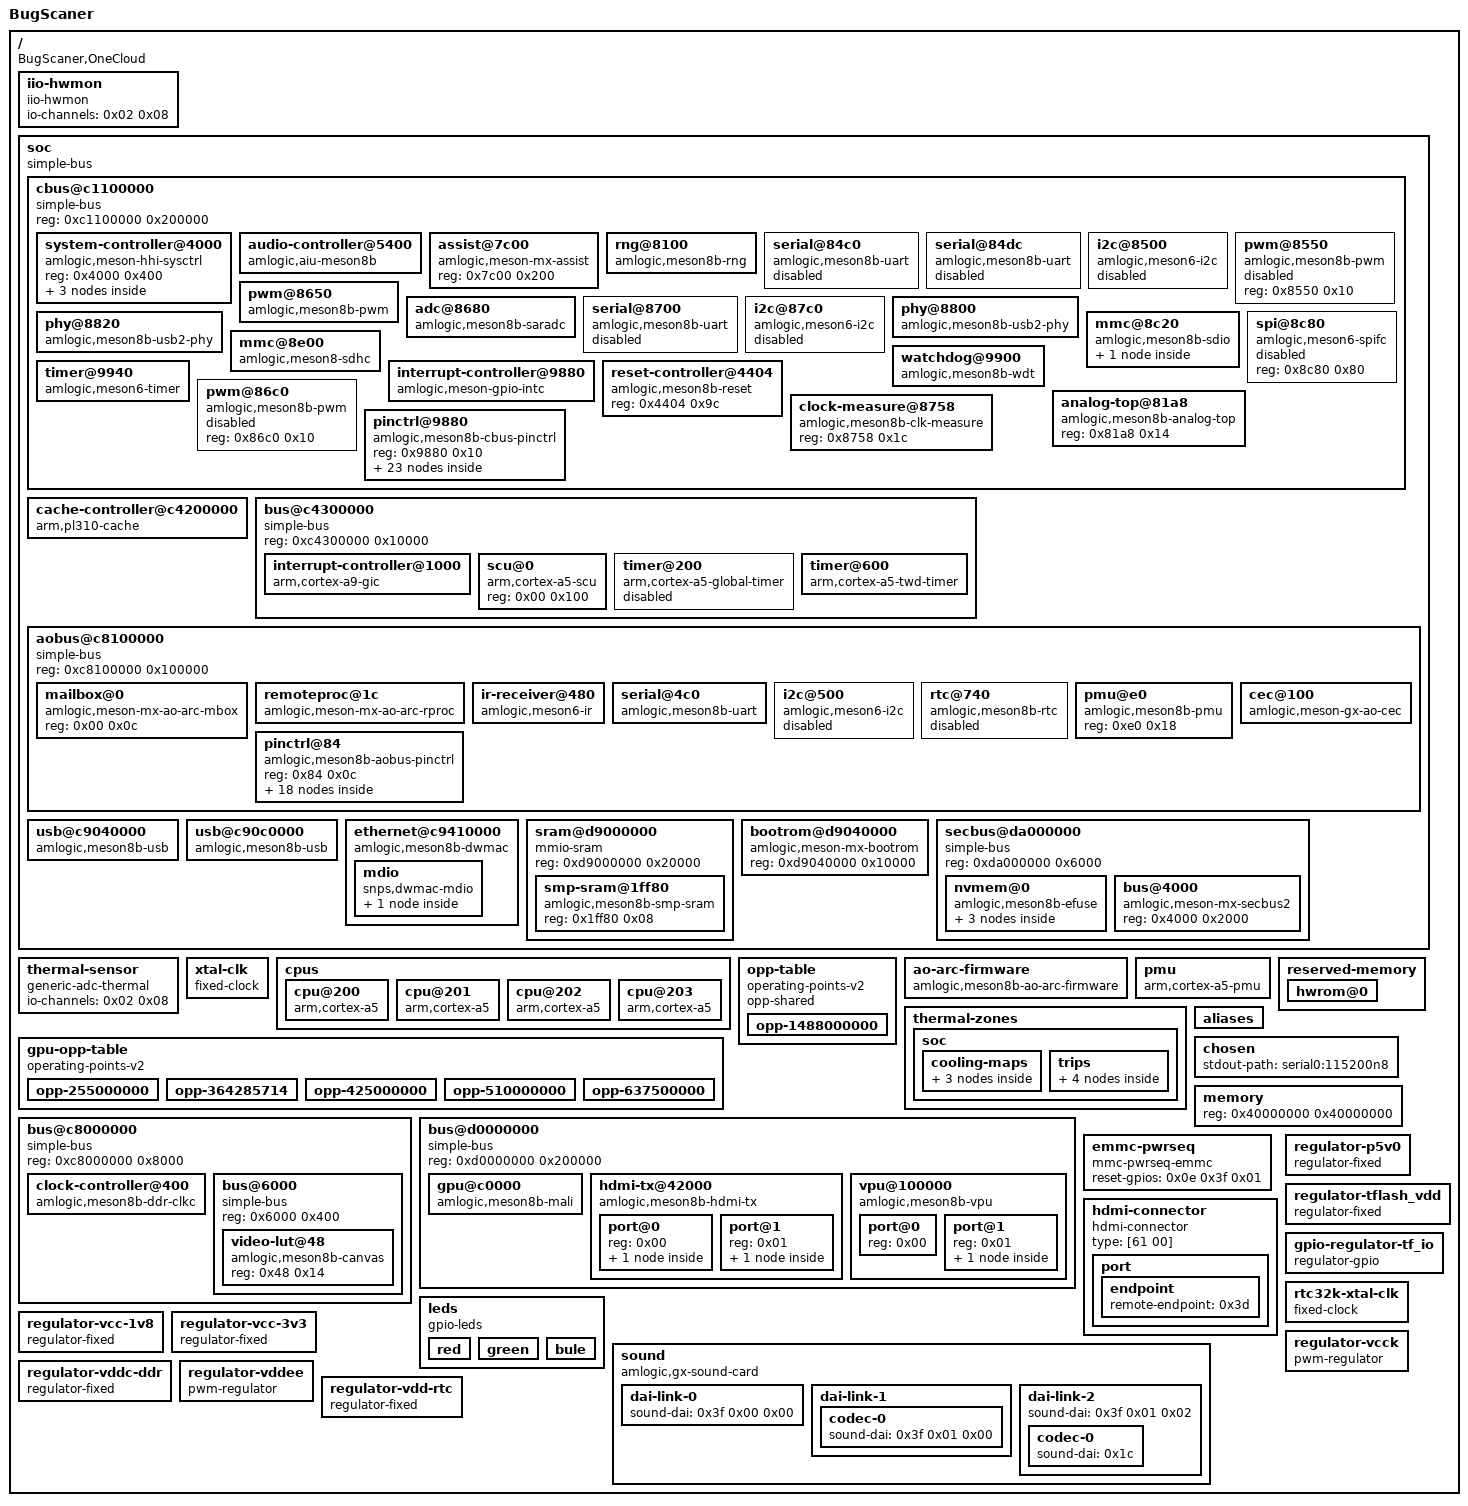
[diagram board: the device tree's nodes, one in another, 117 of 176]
/dts-v1/;

/ {
	#address-cells = <0x01>;
	#size-cells = <0x01>;
	interrupt-parent = <0x01>;
	model = "BugScaner";
	compatible = "BugScaner,OneCloud\0amlogic,meson8b";

	iio-hwmon {
		compatible = "iio-hwmon";
		io-channels = <0x02 0x08>;
	};

	soc {
		compatible = "simple-bus";
		#address-cells = <0x01>;
		#size-cells = <0x01>;
		ranges;

		cbus@c1100000 {
			compatible = "simple-bus";
			reg = <0xc1100000 0x200000>;
			#address-cells = <0x01>;
			#size-cells = <0x01>;
			ranges = <0x00 0xc1100000 0x200000>;

			system-controller@4000 {
				compatible = "amlogic,meson-hhi-sysctrl\0simple-mfd\0syscon";
				reg = <0x4000 0x400>;
				phandle = <0x0a>;

				clock-controller {
					compatible = "amlogic,meson8b-clkc";
					clocks = <0x03 0x04 0x01>;
					clock-names = "xtal\0ddr_pll";
					#clock-cells = <0x01>;
					#reset-cells = <0x01>;
					phandle = <0x05>;
				};

				phy {
					compatible = "amlogic,meson8b-hdmi-tx-phy";
					clocks = <0x05 0x84>;
					#phy-cells = <0x00>;
					phandle = <0x35>;
				};

				power-controller {
					compatible = "amlogic,meson8b-pwrc";
					#power-domain-cells = <0x01>;
					amlogic,ao-sysctrl = <0x06>;
					resets = <0x07 0x42 0x07 0x43 0x07 0x4b 0x07 0x4f 0x07 0x86 0x07 0x87 0x07 0x89 0x07 0x8d 0x07 0x05 0x07 0x0a 0x07 0x85>;
					reset-names = "dblk\0pic_dc\0hdmi_apb\0hdmi_system\0venci\0vencp\0vdac\0vencl\0viu\0venc\0rdma";
					clocks = <0x05 0xbe>;
					clock-names = "vpu";
					assigned-clocks = <0x05 0xbe>;
					assigned-clock-rates = <0xadb4789>;
					phandle = <0x20>;
				};
			};

			audio-controller@5400 {
				compatible = "amlogic,aiu-meson8b\0amlogic,aiu";
				#sound-dai-cells = <0x02>;
				reg = <0x5400 0x2ac>;
				interrupts = <0x00 0x30 0x01 0x00 0x32 0x01>;
				interrupt-names = "i2s\0spdif";
				status = "okay";
				clocks = <0x05 0x26 0x05 0x28 0x05 0x50 0x05 0xd1 0x05 0x2c 0x05 0x27 0x05 0x51 0x05 0xd4 0x05 0xd5>;
				clock-names = "pclk\0i2s_pclk\0i2s_aoclk\0i2s_mclk\0i2s_mixer\0spdif_pclk\0spdif_aoclk\0spdif_mclk\0spdif_mclk_sel";
				resets = <0x07 0x06>;
				phandle = <0x3f>;
			};

			assist@7c00 {
				compatible = "amlogic,meson-mx-assist\0syscon";
				reg = <0x7c00 0x200>;
			};

			rng@8100 {
				compatible = "amlogic,meson8b-rng\0amlogic,meson-rng";
				reg = <0x8100 0x08>;
				clocks = <0x05 0x19>;
				clock-names = "core";
			};

			serial@84c0 {
				compatible = "amlogic,meson8b-uart\0amlogic,meson-uart";
				reg = <0x84c0 0x18>;
				interrupts = <0x00 0x1a 0x01>;
				status = "disabled";
				clocks = <0x05 0x0a 0x03 0x05 0x1a>;
				clock-names = "baud\0xtal\0pclk";
			};

			serial@84dc {
				compatible = "amlogic,meson8b-uart\0amlogic,meson-uart";
				reg = <0x84dc 0x18>;
				interrupts = <0x00 0x4b 0x01>;
				status = "disabled";
				clocks = <0x05 0x0a 0x03 0x05 0x30>;
				clock-names = "baud\0xtal\0pclk";
			};

			i2c@8500 {
				compatible = "amlogic,meson6-i2c";
				reg = <0x8500 0x20>;
				interrupts = <0x00 0x15 0x01>;
				#address-cells = <0x01>;
				#size-cells = <0x00>;
				status = "disabled";
				clocks = <0x05 0x16>;
			};

			pwm@8550 {
				compatible = "amlogic,meson8b-pwm";
				reg = <0x8550 0x10>;
				#pwm-cells = <0x03>;
				status = "disabled";
			};

			pwm@8650 {
				compatible = "amlogic,meson8b-pwm";
				reg = <0x8650 0x10>;
				#pwm-cells = <0x03>;
				status = "okay";
				pinctrl-0 = <0x08 0x09>;
				pinctrl-names = "default";
				clocks = <0x03 0x03>;
				clock-names = "clkin0\0clkin1";
				phandle = <0x41>;
			};

			adc@8680 {
				compatible = "amlogic,meson8b-saradc\0amlogic,meson-saradc";
				reg = <0x8680 0x34>;
				#io-channel-cells = <0x01>;
				interrupts = <0x00 0x49 0x01>;
				status = "okay";
				clocks = <0x03 0x05 0x17>;
				clock-names = "clkin\0core";
				amlogic,hhi-sysctrl = <0x0a>;
				nvmem-cells = <0x0b>;
				nvmem-cell-names = "temperature_calib";
				vref-supply = <0x0c>;
				phandle = <0x02>;
			};

			serial@8700 {
				compatible = "amlogic,meson8b-uart\0amlogic,meson-uart";
				reg = <0x8700 0x18>;
				interrupts = <0x00 0x5d 0x01>;
				status = "disabled";
				clocks = <0x05 0x0a 0x03 0x05 0x44>;
				clock-names = "baud\0xtal\0pclk";
			};

			i2c@87c0 {
				compatible = "amlogic,meson6-i2c";
				reg = <0x87c0 0x20>;
				interrupts = <0x00 0x80 0x01>;
				#address-cells = <0x01>;
				#size-cells = <0x00>;
				status = "disabled";
				clocks = <0x05 0x16>;
			};

			phy@8800 {
				compatible = "amlogic,meson8b-usb2-phy\0amlogic,meson-mx-usb2-phy";
				#phy-cells = <0x00>;
				reg = <0x8800 0x20>;
				status = "okay";
				clocks = <0x05 0x37 0x05 0x32>;
				clock-names = "usb_general\0usb";
				resets = <0x07 0x22>;
				phandle = <0x1d>;
			};

			phy@8820 {
				compatible = "amlogic,meson8b-usb2-phy\0amlogic,meson-mx-usb2-phy";
				#phy-cells = <0x00>;
				reg = <0x8820 0x20>;
				status = "okay";
				clocks = <0x05 0x37 0x05 0x33>;
				clock-names = "usb_general\0usb";
				resets = <0x07 0x22>;
				phandle = <0x1f>;
			};

			mmc@8c20 {
				compatible = "amlogic,meson8b-sdio\0amlogic,meson-mx-sdio";
				reg = <0x8c20 0x20>;
				interrupts = <0x00 0x1c 0x01>;
				#address-cells = <0x01>;
				#size-cells = <0x00>;
				status = "okay";
				clocks = <0x05 0x1e 0x05 0x0a>;
				clock-names = "core\0clkin";
				pinctrl-0 = <0x0d>;
				pinctrl-names = "default";

				slot@1 {
					compatible = "mmc-slot";
					reg = <0x01>;
					status = "okay";
					bus-width = <0x04>;
					no-sdio;
					cap-mmc-highspeed;
					cap-sd-highspeed;
					disable-wp;
					cd-gpios = <0x0e 0x35 0x01>;
					vmmc-supply = <0x0f>;
					vqmmc-supply = <0x10>;
				};
			};

			spi@8c80 {
				compatible = "amlogic,meson6-spifc";
				reg = <0x8c80 0x80>;
				#address-cells = <0x01>;
				#size-cells = <0x00>;
				status = "disabled";
			};

			mmc@8e00 {
				compatible = "amlogic,meson8-sdhc\0amlogic,meson-mx-sdhc";
				reg = <0x8e00 0x42>;
				interrupts = <0x00 0x4e 0x01>;
				status = "okay";
				clocks = <0x03 0x05 0x07 0x05 0x06 0x05 0x08 0x05 0x1b>;
				clock-names = "clkin0\0clkin1\0clkin2\0clkin3\0pclk";
				pinctrl-0 = <0x11>;
				pinctrl-names = "default";
				bus-width = <0x08>;
				max-frequency = <0x5f5e100>;
				disable-wp;
				cap-mmc-highspeed;
				mmc-hs200-1_8v;
				no-sdio;
				mmc-pwrseq = <0x12>;
				vmmc-supply = <0x13>;
				vqmmc-supply = <0x0c>;
			};

			interrupt-controller@9880 {
				compatible = "amlogic,meson-gpio-intc\0amlogic,meson8b-gpio-intc";
				reg = <0x9880 0x10>;
				interrupt-controller;
				#interrupt-cells = <0x02>;
				amlogic,channel-interrupts = <0x40 0x41 0x42 0x43 0x44 0x45 0x46 0x47>;
				status = "okay";
				phandle = <0x24>;
			};

			watchdog@9900 {
				compatible = "amlogic,meson8b-wdt";
				reg = <0x9900 0x08>;
				interrupts = <0x00 0x00 0x01>;
			};

			timer@9940 {
				compatible = "amlogic,meson6-timer";
				reg = <0x9940 0x18>;
				interrupts = <0x00 0x0a 0x01 0x00 0x0b 0x01 0x00 0x06 0x01 0x00 0x1d 0x01>;
				clocks = <0x03 0x05 0x0a>;
				clock-names = "xtal\0pclk";
			};

			reset-controller@4404 {
				compatible = "amlogic,meson8b-reset";
				reg = <0x4404 0x9c>;
				#reset-cells = <0x01>;
				phandle = <0x07>;
			};

			analog-top@81a8 {
				compatible = "amlogic,meson8b-analog-top\0syscon";
				reg = <0x81a8 0x14>;
			};

			pwm@86c0 {
				compatible = "amlogic,meson8b-pwm";
				reg = <0x86c0 0x10>;
				#pwm-cells = <0x03>;
				status = "disabled";
			};

			clock-measure@8758 {
				compatible = "amlogic,meson8b-clk-measure";
				reg = <0x8758 0x1c>;
			};

			pinctrl@9880 {
				compatible = "amlogic,meson8b-cbus-pinctrl";
				reg = <0x9880 0x10>;
				#address-cells = <0x01>;
				#size-cells = <0x01>;
				ranges;
				phandle = <0x14>;

				banks@80b0 {
					reg = <0x80b0 0x28 0x80e8 0x18 0x8120 0x18 0x8030 0x38>;
					reg-names = "mux\0pull\0pull-enable\0gpio";
					gpio-controller;
					#gpio-cells = <0x02>;
					gpio-ranges = <0x14 0x00 0x00 0x53>;
					gpio-line-names = "J2 Header Pin 35\0J2 Header Pin 36\0J2 Header Pin 32\0J2 Header Pin 31\0J2 Header Pin 29\0J2 Header Pin 18\0J2 Header Pin 22\0J2 Header Pin 16\0J2 Header Pin 23\0J2 Header Pin 21\0J2 Header Pin 19\0J2 Header Pin 33\0J2 Header Pin 8\0J2 Header Pin 10\0J2 Header Pin 15\0J2 Header Pin 13\0J2 Header Pin 24\0J2 Header Pin 26\0Revision (upper)\0Revision (lower)\0J2 Header Pin 7\0\0J2 Header Pin 12\0J2 Header Pin 11\0\0\0\0TFLASH_VDD_EN\0\0\0VCCK_PWM (PWM_C)\0I2CA_SDA\0I2CA_SCL\0I2CB_SDA\0I2CB_SCL\0VDDEE_PWM (PWM_D)\0\0HDMI_HPD\0HDMI_I2C_SDA\0HDMI_I2C_SCL\0ETH_PHY_INTR\0ETH_PHY_NRST\0ETH_TXD1\0ETH_TXD0\0ETH_TXD3\0ETH_TXD2\0ETH_RGMII_TX_CLK\0SD_DATA1 (SDB_D1)\0SD_DATA0 (SDB_D0)\0SD_CLK\0SD_CMD\0SD_DATA3 (SDB_D3)\0SD_DATA2 (SDB_D2)\0SD_CDN (SD_DET_N)\0SDC_D0 (EMMC)\0SDC_D1 (EMMC)\0SDC_D2 (EMMC)\0SDC_D3 (EMMC)\0SDC_D4 (EMMC)\0SDC_D5 (EMMC)\0SDC_D6 (EMMC)\0SDC_D7 (EMMC)\0SDC_CLK (EMMC)\0SDC_RSTn (EMMC)\0SDC_CMD (EMMC)\0BOOT_SEL\0\0\0\0\0\0\0\0ETH_RXD1\0ETH_RXD0\0ETH_RX_DV\0RGMII_RX_CLK\0ETH_RXD3\0ETH_RXD2\0ETH_TXEN\0ETH_PHY_REF_CLK_25MOUT\0ETH_MDC\0ETH_MDIO";
					phandle = <0x0e>;
				};

				eth-rgmii {
					phandle = <0x21>;

					mux {
						groups = "eth_tx_clk\0eth_tx_en\0eth_txd1_0\0eth_txd0_0\0eth_rx_clk\0eth_rx_dv\0eth_rxd1\0eth_rxd0\0eth_mdio_en\0eth_mdc\0eth_ref_clk\0eth_txd2\0eth_txd3\0eth_rxd3\0eth_rxd2";
						function = "ethernet";
						bias-disable;
					};
				};

				eth-rmii {

					mux {
						groups = "eth_tx_en\0eth_txd1_0\0eth_txd0_0\0eth_rx_clk\0eth_rx_dv\0eth_rxd1\0eth_rxd0\0eth_mdio_en\0eth_mdc";
						function = "ethernet";
						bias-disable;
					};
				};

				hdmi-hpd {
					phandle = <0x36>;

					mux {
						groups = "hdmi_hpd";
						function = "hdmi";
						bias-disable;
					};
				};

				hdmi-i2c {
					phandle = <0x37>;

					mux {
						groups = "hdmi_sda\0hdmi_scl";
						function = "hdmi";
						bias-disable;
					};
				};

				i2c-a {

					mux {
						groups = "i2c_sda_a\0i2c_sck_a";
						function = "i2c_a";
						bias-disable;
					};
				};

				sd-b {
					phandle = <0x0d>;

					mux {
						groups = "sd_d0_b\0sd_d1_b\0sd_d2_b\0sd_d3_b\0sd_clk_b\0sd_cmd_b";
						function = "sd_b";
						bias-disable;
					};
				};

				sdxc-c {
					phandle = <0x11>;

					mux {
						groups = "sdxc_d0_c\0sdxc_d13_c\0sdxc_d47_c\0sdxc_clk_c\0sdxc_cmd_c";
						function = "sdxc_c";
						bias-pull-up;
					};
				};

				pwm-c1 {
					phandle = <0x08>;

					mux {
						groups = "pwm_c1";
						function = "pwm_c";
						bias-disable;
					};
				};

				pwm-d {
					phandle = <0x09>;

					mux {
						groups = "pwm_d";
						function = "pwm_d";
						bias-disable;
					};
				};

				uart-b0 {

					mux {
						groups = "uart_tx_b0\0uart_rx_b0";
						function = "uart_b";
						bias-disable;
					};
				};

				uart-b0-cts-rts {

					mux {
						groups = "uart_cts_b0\0uart_rts_b0";
						function = "uart_b";
						bias-disable;
					};
				};
			};
		};

		cache-controller@c4200000 {
			compatible = "arm,pl310-cache";
			reg = <0xc4200000 0x1000>;
			cache-unified;
			cache-level = <0x02>;
			arm,data-latency = <0x03 0x03 0x03>;
			arm,tag-latency = <0x02 0x02 0x02>;
			arm,filter-ranges = <0x100000 0xc0000000>;
			prefetch-data = <0x01>;
			prefetch-instr = <0x01>;
			arm,shared-override;
			phandle = <0x25>;
		};

		bus@c4300000 {
			compatible = "simple-bus";
			reg = <0xc4300000 0x10000>;
			#address-cells = <0x01>;
			#size-cells = <0x01>;
			ranges = <0x00 0xc4300000 0x10000>;

			interrupt-controller@1000 {
				compatible = "arm,cortex-a9-gic";
				reg = <0x1000 0x1000 0x100 0x100>;
				interrupt-controller;
				#interrupt-cells = <0x03>;
				phandle = <0x01>;
			};

			scu@0 {
				compatible = "arm,cortex-a5-scu";
				reg = <0x00 0x100>;
			};

			timer@200 {
				compatible = "arm,cortex-a5-global-timer";
				reg = <0x200 0x20>;
				interrupts = <0x01 0x0b 0xf01>;
				clocks = <0x05 0x7e>;
				status = "disabled";
			};

			timer@600 {
				compatible = "arm,cortex-a5-twd-timer";
				reg = <0x600 0x20>;
				interrupts = <0x01 0x0d 0xf01>;
				clocks = <0x05 0x7e>;
			};
		};

		aobus@c8100000 {
			compatible = "simple-bus";
			reg = <0xc8100000 0x100000>;
			#address-cells = <0x01>;
			#size-cells = <0x01>;
			ranges = <0x00 0xc8100000 0x100000>;

			mailbox@0 {
				compatible = "amlogic,meson-mx-ao-arc-mbox";
				reg = <0x00 0x0c>;
				#mbox-cells = <0x01>;
				phandle = <0x29>;
			};

			remoteproc@1c {
				compatible = "amlogic,meson-mx-ao-arc-rproc";
				reg = <0x1c 0x08 0x38 0x08>;
				reg-names = "remap\0cpu";
				amlogic,sram = <0x15>;
				amlogic,secbus2 = <0x16>;
				resets = <0x07 0x4d>;
				reset-names = "arc625";
				phandle = <0x28>;
			};

			ir-receiver@480 {
				compatible = "amlogic,meson6-ir";
				reg = <0x480 0x20>;
				interrupts = <0x00 0x0f 0x01>;
				status = "okay";
				pinctrl-0 = <0x17>;
				pinctrl-names = "default";
			};

			serial@4c0 {
				compatible = "amlogic,meson8b-uart\0amlogic,meson-uart";
				reg = <0x4c0 0x18>;
				interrupts = <0x00 0x5a 0x01>;
				status = "okay";
				clocks = <0x05 0x0a 0x03 0x05 0x0a>;
				clock-names = "baud\0xtal\0pclk";
				pinctrl-0 = <0x18>;
				pinctrl-names = "default";
			};

			i2c@500 {
				compatible = "amlogic,meson6-i2c";
				reg = <0x500 0x20>;
				interrupts = <0x00 0x5c 0x01>;
				#address-cells = <0x01>;
				#size-cells = <0x00>;
				status = "disabled";
				clocks = <0x05 0x0a>;
			};

			rtc@740 {
				compatible = "amlogic,meson8b-rtc";
				reg = <0x740 0x14>;
				interrupts = <0x00 0x48 0x01>;
				#address-cells = <0x01>;
				#size-cells = <0x01>;
				status = "disabled";
				resets = <0x07 0x8a>;
				clocks = <0x19>;
				vdd-supply = <0x1a>;
			};

			pmu@e0 {
				compatible = "amlogic,meson8b-pmu\0syscon";
				reg = <0xe0 0x18>;
				phandle = <0x06>;
			};

			pinctrl@84 {
				compatible = "amlogic,meson8b-aobus-pinctrl";
				reg = <0x84 0x0c>;
				#address-cells = <0x01>;
				#size-cells = <0x01>;
				ranges;
				phandle = <0x1b>;

				ao-bank@14 {
					reg = <0x14 0x04 0x2c 0x04 0x24 0x08>;
					reg-names = "mux\0pull\0gpio";
					gpio-controller;
					#gpio-cells = <0x02>;
					gpio-ranges = <0x1b 0x00 0x00 0x10>;
					gpio-line-names = "UART TX\0UART RX\0\0TF_3V3N_1V8_EN\0USB_HUB_RST_N\0USB_OTG_PWREN\0J7 Header Pin 2\0IR_IN\0J7 Header Pin 4\0J7 Header Pin 6\0J7 Header Pin 5\0J7 Header Pin 7\0HDMI_CEC\0SYS_LED\0\0";
					phandle = <0x3e>;

					usb-hub {
						gpio-hog;
						gpios = <0x04 0x00>;
						output-high;
						line-name = "usb-hub-reset";
					};
				};

				hdmi-cec-ao {

					mux {
						groups = "hdmi_cec_1";
						function = "hdmi_cec";
						bias-pull-up;
					};
				};

				i2s-am-clk-out {

					mux {
						groups = "i2s_am_clk_out";
						function = "i2s";
						bias-disable;
					};
				};

				i2s-ao-clk-out {

					mux {
						groups = "i2s_ao_clk_out";
						function = "i2s";
						bias-disable;
					};
				};

				i2s-lr-clk-out {

					mux {
						groups = "i2s_lr_clk_out";
						function = "i2s";
						bias-disable;
					};
				};

				i2s-out-ch01 {

					mux {
						groups = "i2s_out_01";
						function = "i2s";
						bias-disable;
					};
				};

				spdif-out-1 {

					mux {
						groups = "spdif_out_1";
						function = "spdif_1";
						bias-disable;
					};
				};

				uart_ao_a {
					phandle = <0x18>;

					mux {
						groups = "uart_tx_ao_a\0uart_rx_ao_a";
						function = "uart_ao";
						bias-disable;
					};
				};

				remote {
					phandle = <0x17>;

					mux {
						groups = "remote_input";
						function = "remote";
						bias-disable;
					};
				};
			};

			cec@100 {
				compatible = "amlogic,meson-gx-ao-cec";
				reg = <0x100 0x14>;
				interrupts = <0x00 0x97 0x01>;
				hdmi-phandle = <0x1c>;
			};
		};

		usb@c9040000 {
			compatible = "amlogic,meson8b-usb\0snps,dwc2";
			#address-cells = <0x01>;
			#size-cells = <0x00>;
			reg = <0xc9040000 0x40000>;
			interrupts = <0x00 0x1e 0x04>;
			phys = <0x1d>;
			phy-names = "usb2-phy";
			g-rx-fifo-size = <0x200>;
			g-np-tx-fifo-size = <0x1f4>;
			g-tx-fifo-size = <0x100 0xc0 0x80 0x80 0x80>;
			dr_mode = "peripheral";
			status = "okay";
			clocks = <0x05 0x41>;
			clock-names = "otg";
		};

		usb@c90c0000 {
			compatible = "amlogic,meson8b-usb\0snps,dwc2";
			#address-cells = <0x01>;
			#size-cells = <0x00>;
			reg = <0xc90c0000 0x40000>;
			interrupts = <0x00 0x1f 0x04>;
			phys = <0x1f>;
			phy-names = "usb2-phy";
			dr_mode = "host";
			status = "okay";
			clocks = <0x05 0x40>;
			clock-names = "otg";
		};

		ethernet@c9410000 {
			compatible = "amlogic,meson8b-dwmac\0snps,dwmac-3.70a\0snps,dwmac";
			reg = <0xc9410000 0x10000 0xc1108140 0x04>;
			interrupts = <0x00 0x08 0x04>;
			interrupt-names = "macirq";
			status = "okay";
			clocks = <0x05 0x24 0x05 0x5f 0x05 0x5f 0x05 0x05>;
			clock-names = "stmmaceth\0clkin0\0clkin1\0timing-adjustment";
			rx-fifo-depth = <0x1000>;
			tx-fifo-depth = <0x800>;
			resets = <0x07 0x2b>;
			reset-names = "stmmaceth";
			power-domains = <0x20 0x01>;
			pinctrl-0 = <0x21>;
			pinctrl-names = "default";
			phy-handle = <0x22>;
			phy-mode = "rgmii-rxid";
			nvmem-cells = <0x23>;
			nvmem-cell-names = "mac-address";

			mdio {
				compatible = "snps,dwmac-mdio";
				#address-cells = <0x01>;
				#size-cells = <0x00>;

				ethernet-phy@0 {
					reg = <0x00>;
					reset-assert-us = <0x2710>;
					reset-deassert-us = <0x7530>;
					reset-gpios = <0x0e 0x29 0x01>;
					interrupt-parent = <0x24>;
					interrupts = <0x11 0x08>;
					realtek,led-0-mode = <0x00>;
					realtek,led-1-mode = <0x1a>;
					realtek,led-2-mode = <0x1c>;
					phandle = <0x22>;
				};
			};
		};

		sram@d9000000 {
			compatible = "mmio-sram";
			reg = <0xd9000000 0x20000>;
			#address-cells = <0x01>;
			#size-cells = <0x01>;
			ranges = <0x00 0xd9000000 0x20000>;
			phandle = <0x15>;

			smp-sram@1ff80 {
				compatible = "amlogic,meson8b-smp-sram";
				reg = <0x1ff80 0x08>;
			};
		};

		bootrom@d9040000 {
			compatible = "amlogic,meson-mx-bootrom\0syscon";
			reg = <0xd9040000 0x10000>;
		};

		secbus@da000000 {
			compatible = "simple-bus";
			reg = <0xda000000 0x6000>;
			#address-cells = <0x01>;
			#size-cells = <0x01>;
			ranges = <0x00 0xda000000 0x6000>;

			nvmem@0 {
				compatible = "amlogic,meson8b-efuse";
				reg = <0x00 0x2000>;
				#address-cells = <0x01>;
				#size-cells = <0x01>;
				clocks = <0x05 0x3a>;
				clock-names = "core";

				calib@1f4 {
					reg = <0x1f4 0x04>;
					phandle = <0x0b>;
				};

				calib@1f8 {
					reg = <0x1f8 0x02>;
					phandle = <0x3b>;
				};

				mac@1b4 {
					reg = <0x1b4 0x06>;
					phandle = <0x23>;
				};
			};

			bus@4000 {
				compatible = "amlogic,meson-mx-secbus2";
				reg = <0x4000 0x2000>;
				phandle = <0x16>;
			};
		};
	};

	thermal-sensor {
		compatible = "generic-adc-thermal";
		#thermal-sensor-cells = <0x00>;
		io-channels = <0x02 0x08>;
		io-channel-names = "sensor-channel";
		phandle = <0x2e>;
	};

	xtal-clk {
		compatible = "fixed-clock";
		clock-frequency = <0x16e3600>;
		clock-output-names = "xtal";
		#clock-cells = <0x00>;
		phandle = <0x03>;
	};

	cpus {
		#address-cells = <0x01>;
		#size-cells = <0x00>;

		cpu@200 {
			device_type = "cpu";
			compatible = "arm,cortex-a5";
			next-level-cache = <0x25>;
			reg = <0x200>;
			enable-method = "amlogic,meson8b-smp";
			resets = <0x05 0x03>;
			operating-points-v2 = <0x26>;
			clocks = <0x05 0x0c>;
			#cooling-cells = <0x02>;
			cpu-supply = <0x27>;
			phandle = <0x2a>;
		};

		cpu@201 {
			device_type = "cpu";
			compatible = "arm,cortex-a5";
			next-level-cache = <0x25>;
			reg = <0x201>;
			enable-method = "amlogic,meson8b-smp";
			resets = <0x05 0x04>;
			operating-points-v2 = <0x26>;
			clocks = <0x05 0x0c>;
			#cooling-cells = <0x02>;
			phandle = <0x2b>;
		};

		cpu@202 {
			device_type = "cpu";
			compatible = "arm,cortex-a5";
			next-level-cache = <0x25>;
			reg = <0x202>;
			enable-method = "amlogic,meson8b-smp";
			resets = <0x05 0x05>;
			operating-points-v2 = <0x26>;
			clocks = <0x05 0x0c>;
			#cooling-cells = <0x02>;
			phandle = <0x2c>;
		};

		cpu@203 {
			device_type = "cpu";
			compatible = "arm,cortex-a5";
			next-level-cache = <0x25>;
			reg = <0x203>;
			enable-method = "amlogic,meson8b-smp";
			resets = <0x05 0x06>;
			operating-points-v2 = <0x26>;
			clocks = <0x05 0x0c>;
			#cooling-cells = <0x02>;
			phandle = <0x2d>;
		};
	};

	opp-table {
		compatible = "operating-points-v2";
		opp-shared;
		phandle = <0x26>;
		
		opp-1488000000 {
			opp-hz = <0x00 0x58b11400>;
			opp-microvolt = <0x116520>;
		};

	};

	gpu-opp-table {
		compatible = "operating-points-v2";
		phandle = <0x33>;

		opp-255000000 {
			opp-hz = <0x00 0xf32fdc0>;
			opp-microvolt = <0x10c8e0>;
		};

		opp-364285714 {
			opp-hz = <0x00 0x15b68f12>;
			opp-microvolt = <0x10c8e0>;
		};

		opp-425000000 {
			opp-hz = <0x00 0x1954fc40>;
			opp-microvolt = <0x10c8e0>;
		};

		opp-510000000 {
			opp-hz = <0x00 0x1e65fb80>;
			opp-microvolt = <0x10c8e0>;
		};

		opp-637500000 {
			opp-hz = <0x00 0x25ff7a60>;
			opp-microvolt = <0x10c8e0>;
			turbo-mode;
		};
	};

	ao-arc-firmware {
		compatible = "amlogic,meson8b-ao-arc-firmware";
		amlogic,rproc = <0x28>;
		mboxes = <0x29 0x00 0x29 0x01 0x29 0x02>;
	};

	pmu {
		compatible = "arm,cortex-a5-pmu";
		interrupts = <0x00 0x89 0x04 0x00 0x8a 0x04 0x00 0x99 0x04 0x00 0x9a 0x04>;
		interrupt-affinity = <0x2a 0x2b 0x2c 0x2d>;
	};

	reserved-memory {
		#address-cells = <0x01>;
		#size-cells = <0x01>;
		ranges;

		hwrom@0 {
			reg = <0x00 0x200000>;
			no-map;
		};
	};

	thermal-zones {

		soc {
			polling-delay-passive = <0xfa>;
			polling-delay = <0x3e8>;
			thermal-sensors = <0x2e>;

			cooling-maps {

				map0 {
					trip = <0x2f>;
					cooling-device = <0x2a 0x01 0xffffffff 0x2b 0x01 0xffffffff 0x2c 0x01 0xffffffff 0x2d 0x01 0xffffffff 0x30 0x01 0xffffffff>;
				};

				map1 {
					trip = <0x31>;
					cooling-device = <0x2a 0x03 0xffffffff 0x2b 0x03 0xffffffff 0x2c 0x03 0xffffffff 0x2d 0x03 0xffffffff 0x30 0x02 0xffffffff>;
				};

				map2 {
					trip = <0x32>;
					cooling-device = <0x2a 0x06 0xffffffff 0x2b 0x06 0xffffffff 0x2c 0x06 0xffffffff 0x2d 0x06 0xffffffff 0x30 0x03 0xffffffff>;
				};
			};

			trips {

				soc-alert0 {
					temperature = <0x11170>;
					hysteresis = <0x7d0>;
					type = "passive";
					phandle = <0x2f>;
				};

				soc-alert1 {
					temperature = <0x13880>;
					hysteresis = <0x7d0>;
					type = "passive";
					phandle = <0x31>;
				};

				soc-alert2 {
					temperature = <0x15f90>;
					hysteresis = <0x7d0>;
					type = "hot";
					phandle = <0x32>;
				};

				soc-crit {
					temperature = <0x186a0>;
					hysteresis = <0x7d0>;
					type = "critical";
				};
			};
		};
	};

	bus@c8000000 {
		compatible = "simple-bus";
		reg = <0xc8000000 0x8000>;
		#address-cells = <0x01>;
		#size-cells = <0x01>;
		ranges = <0x00 0xc8000000 0x8000>;

		clock-controller@400 {
			compatible = "amlogic,meson8b-ddr-clkc";
			reg = <0x400 0x20>;
			clocks = <0x03>;
			clock-names = "xtal";
			#clock-cells = <0x01>;
			phandle = <0x04>;
		};

		bus@6000 {
			compatible = "simple-bus";
			reg = <0x6000 0x400>;
			#address-cells = <0x01>;
			#size-cells = <0x01>;
			ranges = <0x00 0x6000 0x400>;

			video-lut@48 {
				compatible = "amlogic,meson8b-canvas\0amlogic,canvas";
				reg = <0x48 0x14>;
				phandle = <0x3a>;
			};
		};
	};

	bus@d0000000 {
		compatible = "simple-bus";
		reg = <0xd0000000 0x200000>;
		#address-cells = <0x01>;
		#size-cells = <0x01>;
		ranges = <0x00 0xd0000000 0x200000>;

		gpu@c0000 {
			compatible = "amlogic,meson8b-mali\0arm,mali-450";
			reg = <0xc0000 0x40000>;
			interrupts = <0x00 0xa0 0x04 0x00 0xa1 0x04 0x00 0xa2 0x04 0x00 0xa3 0x04 0x00 0xa4 0x04 0x00 0xa5 0x04 0x00 0xa6 0x04 0x00 0xa7 0x04>;
			interrupt-names = "gp\0gpmmu\0pp\0pmu\0pp0\0ppmmu0\0pp1\0ppmmu1";
			resets = <0x07 0x4e>;
			clocks = <0x05 0x0a 0x05 0x0b>;
			clock-names = "bus\0core";
			operating-points-v2 = <0x33>;
			#cooling-cells = <0x02>;
			mali-supply = <0x34>;
			phandle = <0x30>;
		};

		hdmi-tx@42000 {
			compatible = "amlogic,meson8b-hdmi-tx";
			reg = <0x42000 0x0c>;
			interrupts = <0x00 0x39 0x01>;
			phys = <0x35>;
			phy-names = "hdmi";
			clocks = <0x05 0x3f 0x05 0xae>;
			clock-names = "pclk\0sys";
			sound-name-prefix = "HDMITX";
			#sound-dai-cells = <0x00>;
			#address-cells = <0x01>;
			#size-cells = <0x00>;
			status = "okay";
			pinctrl-0 = <0x36 0x37>;
			pinctrl-names = "default";
			phandle = <0x1c>;

			port@0 {
				reg = <0x00>;

				endpoint {
					remote-endpoint = <0x38>;
					phandle = <0x3c>;
				};
			};

			port@1 {
				reg = <0x01>;

				endpoint {
					remote-endpoint = <0x39>;
					phandle = <0x3d>;
				};
			};
		};

		vpu@100000 {
			compatible = "amlogic,meson8b-vpu";
			reg = <0x100000 0x10000>;
			reg-names = "vpu";
			interrupts = <0x00 0x03 0x01>;
			amlogic,canvas = <0x3a>;
			amlogic,hhi-sysctrl = <0x0a>;
			clocks = <0x05 0x46 0x05 0x3e 0x05 0x4d 0x05 0x72 0x05 0x83 0x05 0x84 0x05 0x03 0x05 0x89 0x05 0xa7 0x05 0xa3 0x05 0xa5 0x05 0xa1 0x05 0xa9 0x05 0xab>;
			clock-names = "vpu_intr\0hdmi_intr_sync\0venci_int\0hdmi_pll_dco\0hdmi_pll_lvds_od\0hdmi_pll_hdmi_od\0vid_pll\0vid_pll_final_div\0hdmi_tx_pixel\0cts_encp\0cts_enci\0cts_enct\0cts_encl\0vdac";
			resets = <0x05 0x0f 0x05 0x0e 0x05 0x0d 0x05 0x0c>;
			reset-names = "vid_pll_pre\0vid_pll_post\0vid_pll_soft_pre\0vid_pll_soft_post";
			power-domains = <0x20 0x00>;
			nvmem-cells = <0x3b>;
			nvmem-cell-names = "cvbs_trimming";
			#address-cells = <0x01>;
			#size-cells = <0x00>;

			port@0 {
				reg = <0x00>;
			};

			port@1 {
				reg = <0x01>;

				endpoint {
					remote-endpoint = <0x3c>;
					phandle = <0x38>;
				};
			};
		};
	};

	aliases {
		serial0 = "/soc/aobus@c8100000/serial@4c0";
		mmc0 = "/soc/cbus@c1100000/mmc@8c20/slot@1";
		mmc1 = "/soc/cbus@c1100000/mmc@8e00";
	};

	chosen {
		stdout-path = "serial0:115200n8";
	};

	memory {
		device_type = "memory";
		reg = <0x40000000 0x40000000>;
	};

	emmc-pwrseq {
		compatible = "mmc-pwrseq-emmc";
		reset-gpios = <0x0e 0x3f 0x01>;
		phandle = <0x12>;
	};

	hdmi-connector {
		compatible = "hdmi-connector";
		type = [61 00];

		port {

			endpoint {
				remote-endpoint = <0x3d>;
				phandle = <0x39>;
			};
		};
	};

	leds {
		compatible = "gpio-leds";
		
	red {
			label = "onecloud:red:alive";
			gpios = <0x3e 0x0b 0x01>;
			linux,default-trigger = "mmc0";
			default-state = "off";
		};
		
   	green {
			label = "onecloud:green:alive";
			gpios = <0x3e 0x0c 0x01>;
			linux,default-trigger = "default-on";
			default-state = "off";
		};
		
	bule {
			label = "onecloud:bule:alive";
			gpios = <0x3e 0x0d 0x01>;
			linux,default-trigger = "usb-host";
			default-state = "off";
		};
	};

	regulator-p5v0 {
		compatible = "regulator-fixed";
		regulator-name = "P5V0";
		regulator-min-microvolt = <0x4c4b40>;
		regulator-max-microvolt = <0x4c4b40>;
		phandle = <0x40>;
	};

	regulator-tflash_vdd {
		compatible = "regulator-fixed";
		regulator-name = "TFLASH_VDD";
		regulator-min-microvolt = <0x325aa0>;
		regulator-max-microvolt = <0x325aa0>;
		vin-supply = <0x13>;
		gpio = <0x0e 0x1b 0x00>;
		enable-active-high;
		phandle = <0x0f>;
	};

	gpio-regulator-tf_io {
		compatible = "regulator-gpio";
		regulator-name = "TF_IO";
		regulator-min-microvolt = <0x1b7740>;
		regulator-max-microvolt = <0x325aa0>;
		vin-supply = <0x13>;
		gpios = <0x3e 0x03 0x00>;
		gpios-states = <0x00>;
		states = <0x325aa0 0x00 0x1b7740 0x01>;
		phandle = <0x10>;
	};

	rtc32k-xtal-clk {
		compatible = "fixed-clock";
		clock-frequency = <0x8000>;
		clock-output-names = "RTC32K";
		#clock-cells = <0x00>;
		phandle = <0x19>;
	};

	sound {
		compatible = "amlogic,gx-sound-card";
		model = "M8B-ODROID-C1";
		assigned-clocks = <0x05 0x5d 0x05 0x5e>;
		assigned-clock-rates = <0x11940000 0x10266000>;

		dai-link-0 {
			sound-dai = <0x3f 0x00 0x00>;
		};

		dai-link-1 {
			sound-dai = <0x3f 0x00 0x02>;
			dai-format = "i2s";
			mclk-fs = <0x100>;

			codec-0 {
				sound-dai = <0x3f 0x01 0x00>;
			};
		};

		dai-link-2 {
			sound-dai = <0x3f 0x01 0x02>;

			codec-0 {
				sound-dai = <0x1c>;
			};
		};
	};

	regulator-vcc-1v8 {
		compatible = "regulator-fixed";
		regulator-name = "VCC1V8";
		regulator-min-microvolt = <0x1b7740>;
		regulator-max-microvolt = <0x1b7740>;
		vin-supply = <0x40>;
		phandle = <0x0c>;
	};

	regulator-vcc-3v3 {
		compatible = "regulator-fixed";
		regulator-name = "VCC3V3";
		regulator-min-microvolt = <0x325aa0>;
		regulator-max-microvolt = <0x325aa0>;
		vin-supply = <0x40>;
		phandle = <0x13>;
	};

	regulator-vcck {
		compatible = "pwm-regulator";
		regulator-name = "VCCK";
		regulator-min-microvolt = <0xd1f60>;
		regulator-max-microvolt = <0x116520>;
		vin-supply = <0x40>;
		pwms = <0x41 0x00 0x2fba 0x00>;
		pwm-dutycycle-range = <0x5b 0x00>;
		regulator-boot-on;
		regulator-always-on;
		phandle = <0x27>;
	};

	regulator-vddc-ddr {
		compatible = "regulator-fixed";
		regulator-name = "DDR_VDDC";
		regulator-min-microvolt = <0x16e360>;
		regulator-max-microvolt = <0x16e360>;
		vin-supply = <0x40>;
	};

	regulator-vddee {
		compatible = "pwm-regulator";
		regulator-name = "VDDEE";
		regulator-min-microvolt = <0xd1f60>;
		regulator-max-microvolt = <0x116520>;
		vin-supply = <0x40>;
		pwms = <0x41 0x01 0x2fba 0x00>;
		pwm-dutycycle-range = <0x5b 0x00>;
		regulator-boot-on;
		regulator-always-on;
		phandle = <0x34>;
	};

	regulator-vdd-rtc {
		compatible = "regulator-fixed";
		regulator-name = "VDD_RTC";
		regulator-min-microvolt = <0xdbba0>;
		regulator-max-microvolt = <0xdbba0>;
		vin-supply = <0x13>;
		phandle = <0x1a>;
	};
};
